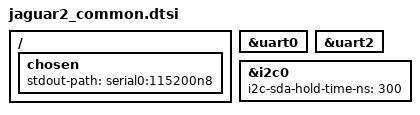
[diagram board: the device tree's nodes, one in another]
// SPDX-License-Identifier: (GPL-2.0+ OR MIT)
/*
 * Copyright (c) 2020 Microsemi Corporation
 */

#include "jaguar2.dtsi"

/ {
	chosen {
		stdout-path = "serial0:115200n8";
	};
};

&uart0 {
	status = "okay";
};

&uart2 {
	status = "okay";
};

&i2c0 {
	status = "okay";
	i2c-sda-hold-time-ns = <300>;
};
